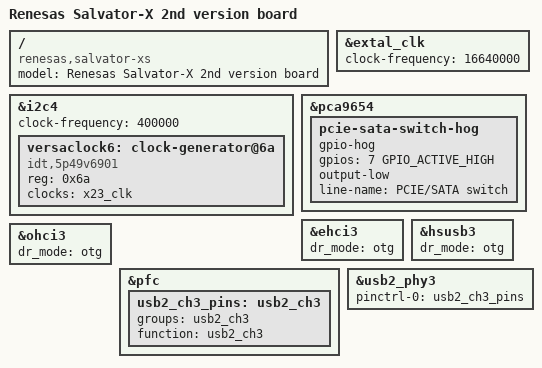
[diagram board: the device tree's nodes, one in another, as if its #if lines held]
#include "salvator-common.dtsi"
/ {
	model = "Renesas Salvator-X 2nd version board";
	compatible = "renesas,salvator-xs";
};
&extal_clk {
	clock-frequency = <16640000>;
};
&i2c4 {
	clock-frequency = <400000>;
	versaclock6: clock-generator@6a {
		compatible = "idt,5p49v6901";
		reg = <0x6a>;
		#clock-cells = <1>;
		clocks = <&x23_clk>;
		clock-names = "xin";
	};
};
#ifdef SOC_HAS_SATA
&pca9654 {
	pcie-sata-switch-hog {
		gpio-hog;
		gpios = <7 GPIO_ACTIVE_HIGH>;
		output-low;  
		line-name = "PCIE/SATA switch";
	};
};
#endif  
#ifdef SOC_HAS_USB2_CH3
&ehci3 {
	dr_mode = "otg";
	status = "okay";
};
&hsusb3 {
	dr_mode = "otg";
	status = "okay";
};
&ohci3 {
	dr_mode = "otg";
	status = "okay";
};
&pfc {
	usb2_ch3_pins: usb2_ch3 {
		groups = "usb2_ch3";
		function = "usb2_ch3";
	};
};
&usb2_phy3 {
	pinctrl-0 = <&usb2_ch3_pins>;
	pinctrl-names = "default";
	status = "okay";
};
#endif  
